# WB32F10x register map
File version: 1.2
CPU: CM3 r2p0, little endian, MPU, no FPU, 4 interrupt priority bits
Registers are 32-bit, read-write, reset 0x0 unless marked. A register's access mark holds for its fields unless they carry their own. Offsets are from the block's base; [hi:lo] are bit positions; {n}, {i} and the like mark numbered series.

## BKP — Backup registers
Base 0x40015C00
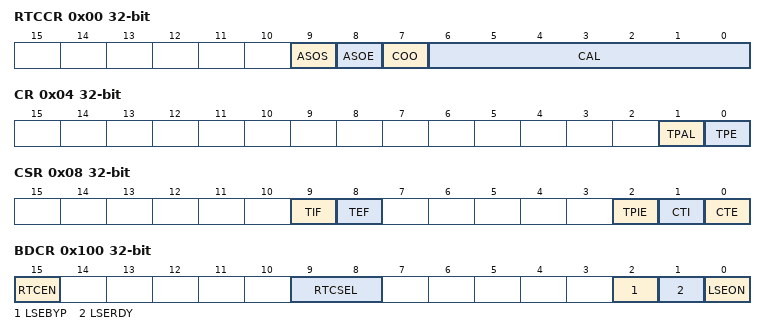
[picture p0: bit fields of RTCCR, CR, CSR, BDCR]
0x00 RTCCR — RTC signal output control register
  [9] ASOS — RTC output selection
  [8] ASOE — RTC alarm or second signal output enable
  [7] COO — RTC clock calibration output enable
  [6:0] CAL — RTC clock calibration value
0x04 CR — Tamper pin control register
  [1] TPAL — TAMPER pin active level
  [0] TPE — TAMPER detection enable
0x08 CSR ro — Tamper control and status register
  [9] TIF — Tamper interrupt flag
  [8] TEF — Tamper event flag
  [2] TPIE — Tamper interrupt enable
  [1] CTI — Tamper interrupt reset
  [0] CTE — Tamper event reset
{0xC+4i} DR{i} (i=1..21) — Backup data register
  [31:0] DATA — Backup data
0x100 BDCR — Backup domain control register
  [15] RTCEN — RTC clock enable control, software set or clear this bit
  [9:8] RTCSEL — RTC clock source selection
  [2] LSEBYP — External Low-speed oscillator bypass
  [1] LSERDY — External low-speed oscillator ready
  [0] LSEON — External low-speed oscillator enable Set and cleared by software

## AFIO — AFIO registers
Base 0x40001400
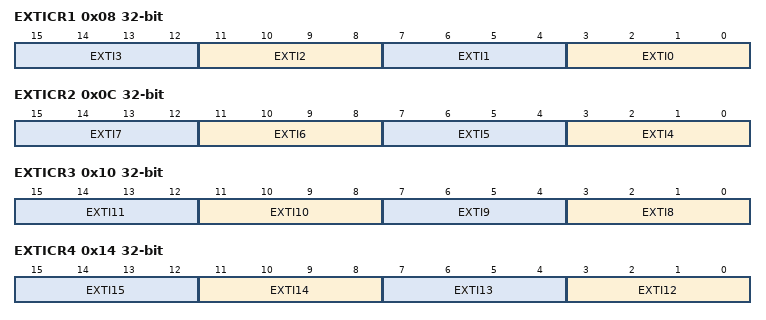
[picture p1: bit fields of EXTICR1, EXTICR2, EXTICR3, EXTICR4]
0x08 EXTICR1 — External interrupt configuration register 1
  [4n+3:4n] EXTI{n} (n=0..3) — EXTI x configuration {n}
0x0C EXTICR2 — External interrupt configuration register 2
  [4n-13:4n-16] EXTI{n} (n=4..7) — EXTI x configuration {n}
0x10 EXTICR3 — External interrupt configuration register 3
  [4n-29:4n-32] EXTI{n} (n=8..11) — EXTI x configuration {n}
0x14 EXTICR4 — External interrupt configuration register 4
  [4n-45:4n-48] EXTI{n} (n=12..15) — EXTI x configuration {n}

## GPIOA — General-purpose and alternate-function I/O
Base 0x40000000
Same registers: GPIOB 0x40000400, GPIOC 0x40000800, GPIOD 0x40000C00
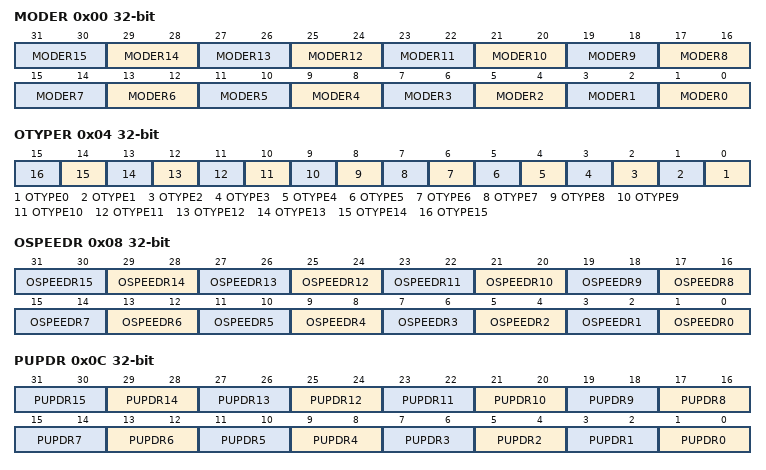
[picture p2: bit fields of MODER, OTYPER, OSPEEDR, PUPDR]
0x00 MODER — GPIO port mode register
  [2n+1:2n] MODER{n} (n=0..15) — Port x configuration bits {n}
    0=Input mode; 1=Output (General purpose output mode); 2=Alternate function mode; 3=Analog mode
0x04 OTYPER — GPIO port output type register
  [n] OTYPE{n} (n=0..15) — Port x configuration bits {n}
    0=Push-Pull (Output push-pull); 1=Open-Drain (Output open-drain)
0x08 OSPEEDR — GPIO port output speed register
  [2n+1:2n] OSPEEDR{n} (n=0..15) — Port x configuration bits {n}
    0=Speed (High speed); 1=Speed (Low speed)
0x0C PUPDR — GPIO port pull-up/pull-down register
  [2n+1:2n] PUPDR{n} (n=0..15) — Port x configuration bits {n}
    0=Pull (No pull-up or pull-down); 1=Pull-up; 1=Pull-down; 3=Pull (Reserved)
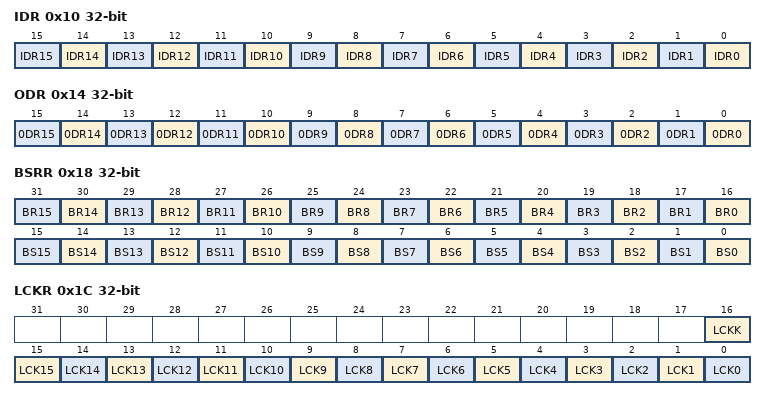
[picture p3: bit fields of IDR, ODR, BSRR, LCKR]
0x10 IDR ro — GPIO port input data register
  [n] IDR{n} (n=0..15) — Port input data {n}
0x14 ODR — GPIO port output data register
  [n] 0DR{n} (n=0..15) — Port putput data {n}
0x18 BSRR write — GPIO port bit set/reset register
  [n+16] BR{n} (n=0..15) — Port x reset bit {n}
  [n] BS{n} (n=0..15) — Port x set bit {n}
0x1C LCKR — GPIO port configuration lock register
  [16] LCKK — This bit can be read any time. It can only be modified using the lock key write sequence
  [n] LCK{n} (n=0..15) — Port x lock bit {n}
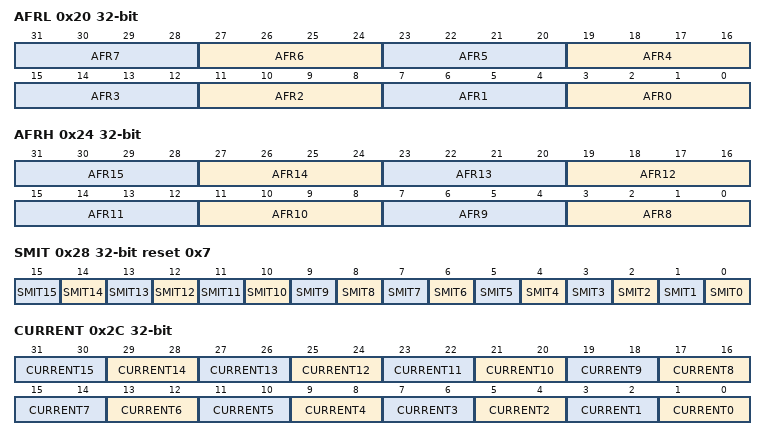
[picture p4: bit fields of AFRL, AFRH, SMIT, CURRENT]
0x20 AFRL — GPIO alternate function low register
  [4n+3:4n] AFR{n} (n=0..7) — Alternate function selection for port x pin {n}
0x24 AFRH — GPIO alternate function high register
  [4n-29:4n-32] AFR{n} (n=8..15) — Alternate function selection for port x pin {n}
0x28 SMIT reset 0x7 — GPIO Port Schmitt Register
  [n] SMIT{n} (n=0..15) — Port x configuration bit {n}
0x2C CURRENT — GPIO Port driver register
  [2n+1:2n] CURRENT{n} (n=0..15) — Port x configuration bits {n}
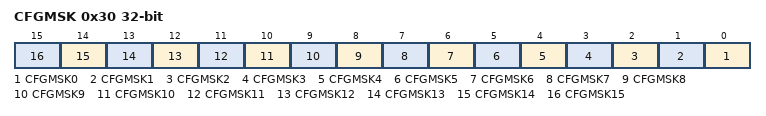
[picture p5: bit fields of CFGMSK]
0x30 CFGMSK — GPIO Port configuration auxiliary register
  [n] CFGMSK{n} (n=0..15) — Port x lock bit {n}

## SYS — System configuration
Base 0x40016400
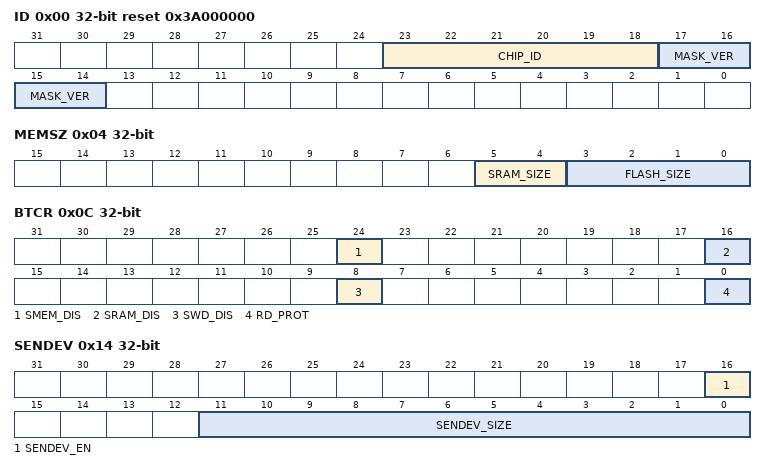
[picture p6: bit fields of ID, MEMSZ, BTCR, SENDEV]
0x00 ID ro reset 0x3A000000 (reset mask 0xFF000000)
  [23:18] CHIP_ID — Part No
  [17:14] MASK_VER — MASK version
0x04 MEMSZ ro reset not defined — Memory control Register
  [5:4] SRAM_SIZE — SRAM density
  [3:0] FLASH_SIZE — FLASH density
0x0C BTCR ro reset not defined — Security control Register
  [24] SMEM_DIS — System memory boot control
  [16] SRAM_DIS — SRAM boot contro
  [8] SWD_DIS — SWD control
  [0] RD_PROT — Read protection control
0x10 MEMWEN ro reset not defined — FLASH write protection register
  [31:0] MAIN_WEN — FLASH Write protection control
0x14 SENDEV ro reset not defined — Secondary development control Register
  [16] SENDEV_EN — Secondary development control
  [11:0] SENDEV_SIZE — Secondary development code space control, the granuality is 1K Byte
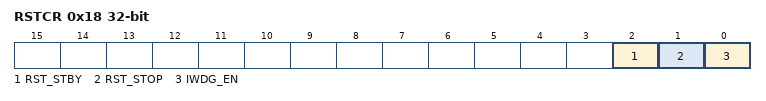
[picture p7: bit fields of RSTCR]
0x18 RSTCR ro (reset mask 0xFFFFFFF0) — Reboot control Register
  [2] RST_STBY — Standby Mode reset control
  [1] RST_STOP — Stop mode reset control
  [0] IWDG_EN — IWDG start control
{0xC+4i} IF{i}LCK ro (reset mask 0xFFFFFFF0) (i=4..7) — Information block {i} protection register
  [0] SYS_IF{i}LCK — {i}th Information block Erase/Write control
0x34 BTSR ro reset 0x2 — Boot control Register
  [1:0] BOOT_MODE
